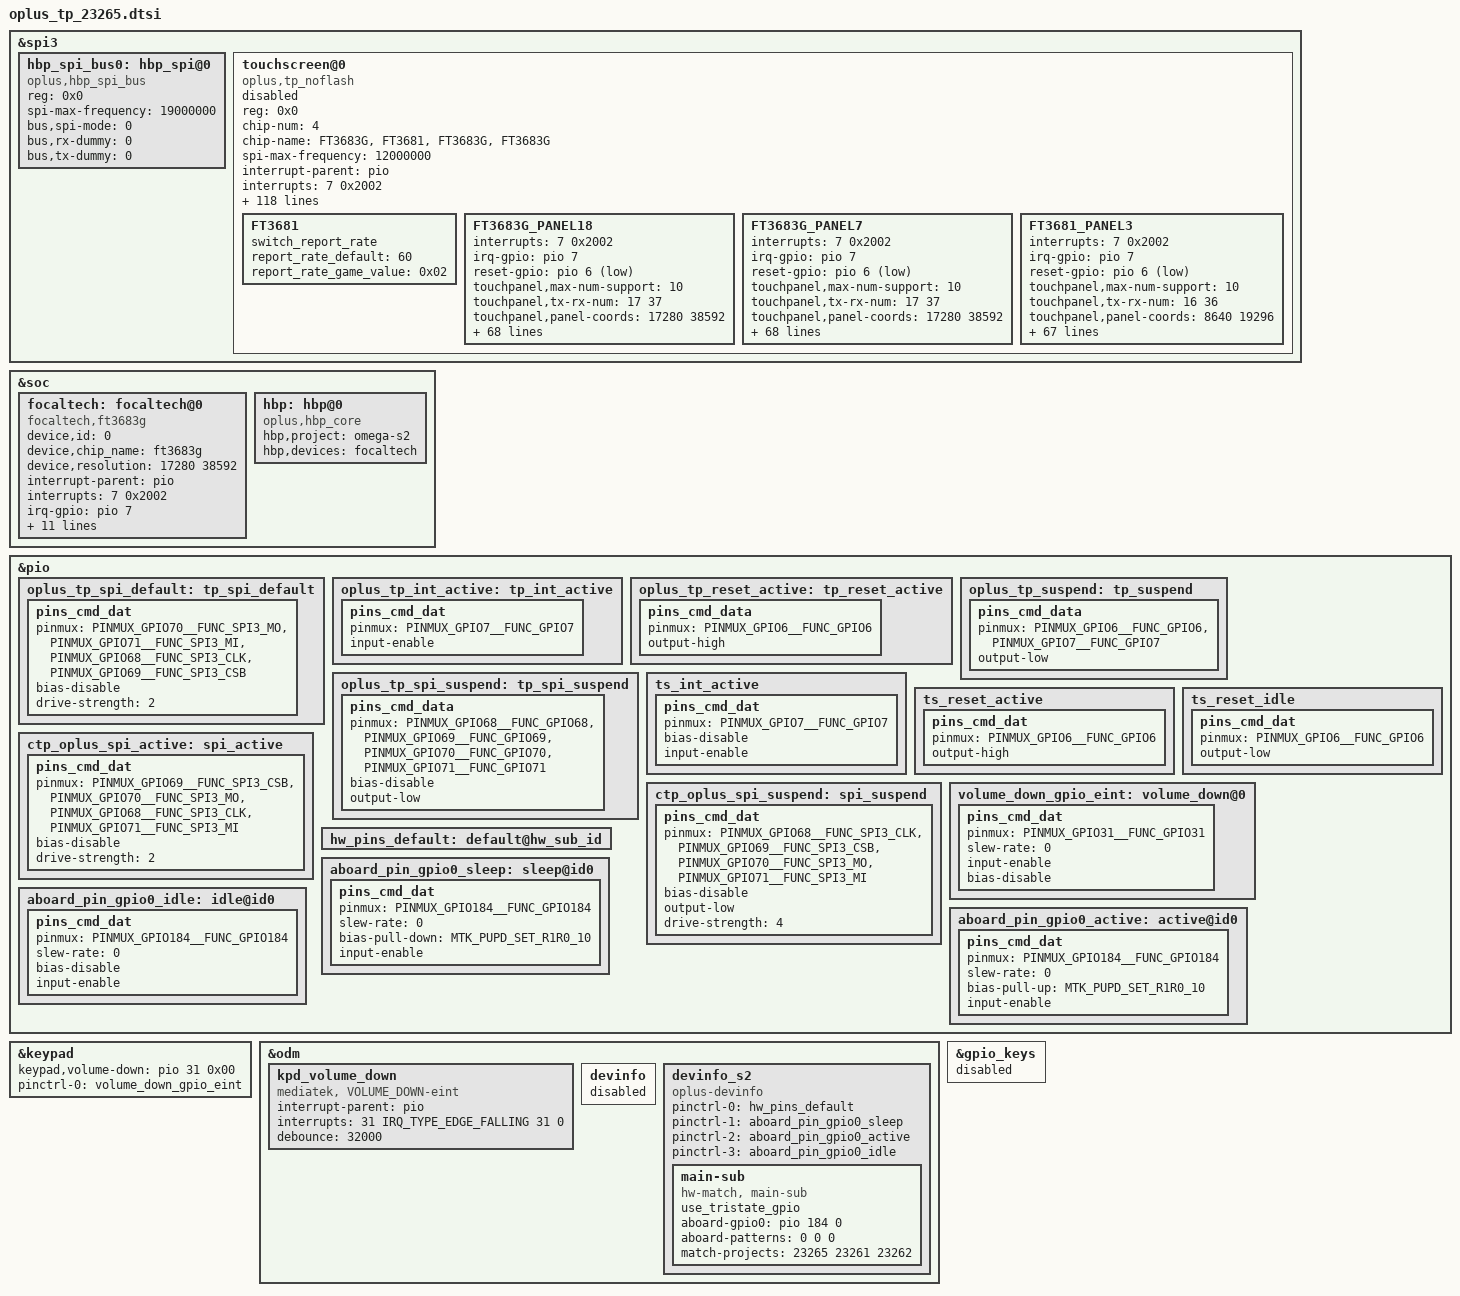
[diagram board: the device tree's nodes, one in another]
&spi3 {
	status = "okay";
	#address-cells = <1>;
	#size-cells = <0>;

	hbp_spi_bus0:hbp_spi@0 {
		compatible = "oplus,hbp_spi_bus";
		reg = <0x0>;
		status = "okay";

		spi-max-frequency = <19000000>;
		bus,spi-mode = <0>;
		bus,rx-dummy = <0>;
		bus,tx-dummy = <0>;
	};

	touchscreen@0{
		compatible = "oplus,tp_noflash";
		reg = <0x0>;
		chip-num = <4>;
		chip-name = "FT3683G", "FT3681", "FT3683G", "FT3683G";
		status = "disabled";
		spi-max-frequency = <12000000>;
		/* Interrupt && Irq-gpio */
		interrupt-parent = <&pio>;
		interrupts = <7 0x2002>;

		/* Power Config */
		vdd_2v8-supply  = <&wl28681c1_ldo6a>;
		vdd_2v8_volt = <3204000>;
		vcc_1v8-supply  = <&mt6369_vtp>;
		vcc_1v8_volt = <1800000>;


		/* Other HW Resource */

		irq-gpio = <&pio 7 0x2002>;
		reset-gpio = <&pio 6 0x1>;

		pinctrl-names = "default",  "sleep";
		pinctrl-0 = <&oplus_tp_int_active &oplus_tp_reset_active &oplus_tp_spi_default>;
		pinctrl-1 = <&oplus_tp_suspend &oplus_tp_spi_suspend>;

		touchpanel,max-num-support = <10>;
		touchpanel,tx-rx-num = <17 37>;
		touchpanel,panel-coords = <17280 38592>;
		touchpanel,display-coords = <1080 2412>;
		touchpanel,touchmajor-limit = <128 216>;
		//touchpanel,elimination-range = <20 200 200>;
		//touchpanel,int-mode = <1>; /*0: interrupt and disable, 1:interrupt and not disable*/
		touchpanel,smooth-level = <0 110 115 120 140 155>;
		touchpanel,smooth-level-charging = <0 110 115 120 140 155>;
		touchpanel,sensitive-level = <0 19 16 12 11 10>;
		touchpanel,tp-index = <0>;
		touchpanel,high-frame-rate-time = <60>;
		disable_suspend_irq_handler_support;

		vid_len = <2>;
		firmware_name = "0xAC16400", "0xAC16401", "0xAC15800", "AC15801";
		panel_type = <7 3 7 18>; /* panel-BOE*/
		platform_support_project = <23265 23262 23261>;
		platform_support_project_dir = <23265 23265 23265>;
		platform_support_project_commandline = "ac164_p_7_a0001_cmd_panel_lcm_drv", "ac164_p_3_a0001_cmd_panel_lcm_drv", "ac158_p_7_a0001_cmd_panel_lcm_drv", "ac158_p_b_a0012_cmd_panel_lcm_drv";

		prevention,curved_screen_V2;
		prevention,grip_disable_level = <6>;
		prevention,updelay_time_ms = <30>;
		prevention,makeup_cnt_weight = <4 1 2 2 2>;
		prevention,large_corner_range = <1920 4800>;
		prevention,large_corner_judge_condition = <500 300 1600 6 6>;
		prevention,trx_reject_condition = <8 7 7>;
		prevention,trx_strict_reject_condition = <7 6 6>;
		prevention,large_judge_time_ms = <500 50 30>;
		prevention,large_exit_condition = <15 12 2>;
		prevention,single_channel_width = <256 256>;
		prevention,normal_tap_condition = <10 300>;
		prevention,long_edge_condition = <230 100 180 80>;
		prevention,long_strict_edge_condition = <170 80>;
		prevention,long_fingerhold_condition = <50 6 4 4>;
		prevention,short_edge_condition = <230 100 180 80>;
		prevention,short_strict_edge_condition = <160 60>;
		prevention,large_strict_exit_condition = <5 5>;
		prevention,top_corner_config = <800 2400 720>;
		prevention,edge_swipe_config = <480 1600>;

		prevention,curved_screen_V4;
		prevention,long_eliminate_point_type = <2 17280 13280 420 38592 300 1>;
		prevention,long_fingerhold_condition2 = <1120 3200 0 0>;
		prevention,top_corner_config2 =<3 80 420 2400 0>;
		prevention,hor_long_top_corner_config =<480 3200 0 0>;
		prevention,top_middle_config =<17280 1600 1600 0>;
		prevention,corner_eliminate_point_type =<0 1920 3200 1>;
		prevention,finger_hold_differ_size = <1 0 720 300>;
		prevention,finger_hold_max_rx_exit_distance = <5 700 3400>;
		prevention,max_rx_exit_distance = <1 5 18 700 2800>;
		prevention,dynamic_finger_hold_exit_distance = <1 580 3400 780>;
		prevention,edge_sliding_matched_support = <1 250 3 0>;

		//grip v4.2 reclining mode
		prevention,reclining_mode_support = <1>;
		prevention,long_eliminate_point_type_recli = <2 17280 13280 420 38592 200 1>;
		prevention,finger_hold_differ_size_recli = <1 0 720 300>;
		prevention,finger_hold_max_rx_exit_distance_recli = <5 700 3400>;
		prevention,max_rx_exit_distance_recli = <1 5 90 700 2800>;
		prevention,dynamic_finger_hold_exit_distance_recli = <1 580 3400 780>;
		prevention,edge_sliding_matched_support_recli = <1 200 3 0>;
		prevention,long_edge_condition_recli = <120 100 150 100>;

		/* SW Support Feature Control */
		//esd_handle_support;
		//register-is-16bit;
		//wireless_charger_support;
		headset_pump_support;
		//fw_edge_limit_support;

		health_monitor_v2_support;
		black_gesture_support;
		charger_pump_support;
		lcd_tp_refresh_support;
		fw_update_app_support;
		smart_gesture_support;
		game_switch_support;
		report_flow_unlock_support;
		kernel_grip_support;
		fingerprint_underscreen_support;
		pressure_report_support;
		touchpanel,single-optimized-time = <8>;
		//report_rate_white_list_support;
		auto_test_force_pass_support;
		snr_read_support;
		//high_resolution_support;
		screenoff_fingerprint_info_support;
		irq_need_dev_resume_ok;
		sportify_aod_gesture_support;
		black_gesture_indep_support;
		thermal_detect_support;
		exception_upload_support;
		tp_data_record_support;
		palm_to_sleep_support;

		/*
		 *Virtual Key Config:
		 *1:touchpanel,button-type: <virtualkey_type  supportted_button-map>
		 *virtualkey_type:
		 *Type 1: using board_properties
		 *Type 2: using same IC (button zone&& touch zone are seprate)
		 *Type 3: using diffrent IC (button zone&& touch zone are seprate)
		 *Type 4: No need of virtual key process
		 *supportted_button-map:select|menu|home|back
		 *
		 *2:touchpanel,button-map
		 *type (X1,Y1)(X2,Y2)(X3,Y3)(Width_X,Hight_Y)--Only when button-type is 0
		 */
		touchpanel,button-type = <4>;
		touchpanel.button-TRx = <0 0>;

		FT3681 {
			switch_report_rate;
			report_rate_default = <60>;
			report_rate_game_value = <0x02>;
		};

		FT3683G_PANEL18 {
			interrupts = <7 0x2002>;
			irq-gpio = <&pio 7 0x2002>;
			reset-gpio = <&pio 6 0x1>;

			touchpanel,max-num-support = <10>;
			touchpanel,tx-rx-num = <17 37>;
			touchpanel,panel-coords = <17280 38592>;
			touchpanel,display-coords = <1080 2412>;
			touchpanel,touchmajor-limit = <128 216>;
			//touchpanel,elimination-range = <20 200 200>;
			//touchpanel,int-mode = <1>; /*0: interrupt and disable, 1:interrupt and not disable*/
			touchpanel,smooth-level = <0 110 115 120 140 155>;
			touchpanel,smooth-level-charging = <0 110 115 120 140 155>;
			touchpanel,sensitive-level = <0 19 16 12 11 10>;
			touchpanel,tp-index = <0>;
			touchpanel,high-frame-rate-time = <60>;

			prevention,curved_screen_V2;
			prevention,grip_disable_level = <6>;
			prevention,updelay_time_ms = <30>;
			prevention,makeup_cnt_weight = <4 1 2 2 2>;
			prevention,large_corner_range = <1920 4800>;
			prevention,large_corner_judge_condition = <500 300 1600 6 6>;
			prevention,trx_reject_condition = <8 7 7>;
			prevention,trx_strict_reject_condition = <7 6 6>;
			prevention,large_judge_time_ms = <500 50 30>;
			prevention,large_exit_condition = <15 12 2>;
			prevention,single_channel_width = <256 256>;
			prevention,normal_tap_condition = <10 300>;
			prevention,long_edge_condition = <230 100 180 80>;
			prevention,long_strict_edge_condition = <170 80>;
			prevention,long_fingerhold_condition = <50 6 4 4>;
			prevention,short_edge_condition = <230 100 180 80>;
			prevention,short_strict_edge_condition = <160 60>;
			prevention,large_strict_exit_condition = <5 5>;
			prevention,top_corner_config = <800 2400 720>;
			prevention,edge_swipe_config = <480 1600>;

			prevention,curved_screen_V4;
			prevention,long_eliminate_point_type = <2 17280 13280 420 38592 300 1>;
			prevention,long_fingerhold_condition2 = <1120 3200 0 0>;
			prevention,top_corner_config2 =<3 80 420 2400 0>;
			prevention,hor_long_top_corner_config =<480 3200 0 0>;
			prevention,top_middle_config =<17280 1600 1600 0>;
			prevention,corner_eliminate_point_type =<0 1920 3200 1>;
			prevention,finger_hold_differ_size = <1 0 720 300>;
			prevention,finger_hold_max_rx_exit_distance = <5 700 3400>;
			prevention,max_rx_exit_distance = <1 5 18 700 2800>;
			prevention,dynamic_finger_hold_exit_distance = <1 580 3400 780>;
			prevention,edge_sliding_matched_support = <1 250 3 0>;

			//grip v4.2 reclining mode
			prevention,reclining_mode_support = <1>;
			prevention,long_eliminate_point_type_recli = <2 17280 13280 420 38592 200 1>;
			prevention,finger_hold_differ_size_recli = <1 0 720 300>;
			prevention,finger_hold_max_rx_exit_distance_recli = <5 700 3400>;
			prevention,max_rx_exit_distance_recli = <1 5 90 700 2800>;
			prevention,dynamic_finger_hold_exit_distance_recli = <1 580 3400 780>;
			prevention,edge_sliding_matched_support_recli = <1 200 3 0>;
			prevention,long_edge_condition_recli = <120 100 150 100>;

			tp_data_record_support;
		};


		FT3683G_PANEL7 {
			interrupts = <7 0x2002>;
			irq-gpio = <&pio 7 0x2002>;
			reset-gpio = <&pio 6 0x1>;

			touchpanel,max-num-support = <10>;
			touchpanel,tx-rx-num = <17 37>;
			touchpanel,panel-coords = <17280 38592>;
			touchpanel,display-coords = <1080 2412>;
			touchpanel,touchmajor-limit = <128 216>;
			//touchpanel,elimination-range = <20 200 200>;
			//touchpanel,int-mode = <1>; /*0: interrupt and disable, 1:interrupt and not disable*/
			touchpanel,smooth-level = <0 110 115 120 140 155>;
			touchpanel,smooth-level-charging = <0 110 115 120 140 155>;
			touchpanel,sensitive-level = <0 19 16 12 11 10>;
			touchpanel,tp-index = <0>;
			touchpanel,high-frame-rate-time = <60>;

			prevention,curved_screen_V2;
			prevention,grip_disable_level = <6>;
			prevention,updelay_time_ms = <30>;
			prevention,makeup_cnt_weight = <4 1 2 2 2>;
			prevention,large_corner_range = <1920 4800>;
			prevention,large_corner_judge_condition = <500 300 1600 6 6>;
			prevention,trx_reject_condition = <8 7 7>;
			prevention,trx_strict_reject_condition = <7 6 6>;
			prevention,large_judge_time_ms = <500 50 30>;
			prevention,large_exit_condition = <15 12 2>;
			prevention,single_channel_width = <256 256>;
			prevention,normal_tap_condition = <10 300>;
			prevention,long_edge_condition = <230 100 180 80>;
			prevention,long_strict_edge_condition = <170 80>;
			prevention,long_fingerhold_condition = <50 6 4 4>;
			prevention,short_edge_condition = <230 100 180 80>;
			prevention,short_strict_edge_condition = <160 60>;
			prevention,large_strict_exit_condition = <5 5>;
			prevention,top_corner_config = <800 2400 720>;
			prevention,edge_swipe_config = <480 1600>;

			prevention,curved_screen_V4;
			prevention,long_eliminate_point_type = <2 17280 13280 420 38592 300 1>;
			prevention,long_fingerhold_condition2 = <1120 3200 0 0>;
			prevention,top_corner_config2 =<3 80 420 2400 0>;
			prevention,hor_long_top_corner_config =<480 3200 0 0>;
			prevention,top_middle_config =<17280 1600 1600 0>;
			prevention,corner_eliminate_point_type =<0 1920 3200 1>;
			prevention,finger_hold_differ_size = <1 0 720 300>;
			prevention,finger_hold_max_rx_exit_distance = <5 700 3400>;
			prevention,max_rx_exit_distance = <1 5 18 700 2800>;
			prevention,dynamic_finger_hold_exit_distance = <1 580 3400 780>;
			prevention,edge_sliding_matched_support = <1 250 3 0>;

			//grip v4.2 reclining mode
			prevention,reclining_mode_support = <1>;
			prevention,long_eliminate_point_type_recli = <2 17280 13280 420 38592 200 1>;
			prevention,finger_hold_differ_size_recli = <1 0 720 300>;
			prevention,finger_hold_max_rx_exit_distance_recli = <5 700 3400>;
			prevention,max_rx_exit_distance_recli = <1 5 90 700 2800>;
			prevention,dynamic_finger_hold_exit_distance_recli = <1 580 3400 780>;
			prevention,edge_sliding_matched_support_recli = <1 200 3 0>;
			prevention,long_edge_condition_recli = <120 100 150 100>;

			tp_data_record_support;
		};

		FT3681_PANEL3 {
			interrupts = <7 0x2002>;
			irq-gpio = <&pio 7 0x2002>;
			reset-gpio = <&pio 6 0x1>;

			touchpanel,max-num-support = <10>;
			touchpanel,tx-rx-num = <16 36>;
			touchpanel,panel-coords = <8640 19296>;
			touchpanel,display-coords = <1080 2412>;
			touchpanel,touchmajor-limit = <128 216>;
			//touchpanel,elimination-range = <20 200 200>;
			//touchpanel,int-mode = <1>; /*0: interrupt and disable, 1:interrupt and not disable*/
			touchpanel,smooth-level = <0 110 115 120 140 155>;
			touchpanel,smooth-level-charging = <0 110 115 120 140 155>;
			touchpanel,sensitive-level = <0 19 16 12 11 10>;
			touchpanel,tp-index = <0>;
			touchpanel,high-frame-rate-time = <60>;

			prevention,curved_screen_V2;
			prevention,grip_disable_level = <6>;
			prevention,updelay_time_ms = <30>;
			prevention,makeup_cnt_weight = <4 1 2 2 2>;
			prevention,large_corner_range = <960 2400>;
			prevention,large_corner_judge_condition = <500 300 800 6 6>;
			prevention,trx_reject_condition = <8 7 7>;
			prevention,trx_strict_reject_condition = <7 6 6>;
			prevention,large_judge_time_ms = <500 50 30>;
			prevention,large_exit_condition = <15 12 2>;
			prevention,single_channel_width = <256 256>;
			prevention,normal_tap_condition = <10 300>;
			prevention,long_edge_condition = <230 100 180 80>;
			prevention,long_strict_edge_condition = <170 80>;
			prevention,long_fingerhold_condition = <50 6 4 4>;
			prevention,short_edge_condition = <230 100 180 80>;
			prevention,short_strict_edge_condition = <160 60>;
			prevention,large_strict_exit_condition = <5 5>;
			prevention,top_corner_config = <400 1200 380>;
			prevention,edge_swipe_config = <240 800>;

			prevention,curved_screen_V4;
			prevention,long_eliminate_point_type = <2 8640 6640 210 19296 300 1>;
			prevention,long_fingerhold_condition2 = <560 1600 0 0>;
			prevention,top_corner_config2 =<3 80 420 1200 0>;
			prevention,hor_long_top_corner_config =<240 1600 0 0>;
			prevention,top_middle_config =<8640 800 800 0>;
			prevention,corner_eliminate_point_type =<0 960 1600 1>;
			prevention,finger_hold_differ_size = <1 0 360 300>;
			prevention,finger_hold_max_rx_exit_distance = <5 350 1700>;
			prevention,max_rx_exit_distance = <1 5 90 350 1400>;
			prevention,dynamic_finger_hold_exit_distance = <1 290 1700 390>;
			prevention,edge_sliding_matched_support = <1 250 3 0>;

			//grip v4.2 reclining mode
			prevention,reclining_mode_support = <1>;
			prevention,long_eliminate_point_type_recli = <2 8640 6640 210 19296 200 1>;
			prevention,finger_hold_differ_size_recli = <1 0 360 300>;
			prevention,finger_hold_max_rx_exit_distance_recli = <5 350 1700>;
			prevention,max_rx_exit_distance_recli = <1 5 90 350 1400>;
			prevention,dynamic_finger_hold_exit_distance_recli = <1 290 1700 390>;
			prevention,edge_sliding_matched_support_recli = <1 200 3 0>;
			prevention,long_edge_condition_recli = <120 100 150 100>;

			tp_data_record_support;
		};
	};
};

&soc {
	focaltech:focaltech@0 {
		compatible = "focaltech,ft3683g";
		status = "okay";

		device,id = <0>;
		device,chip_name = "ft3683g";
		device,resolution = <17280 38592>;

		/*interrupt config*/
		interrupt-parent = <&pio>;
		interrupts = <7 0x2002>;
		irq-gpio = <&pio 7 0x2002>;

		pinctrl-names = "default",
			"ts_reset_active",
			"ts_reset_idle",
			"ts_resume",
			"ts_suspend";
		pinctrl-0 = <&ts_int_active &ts_reset_active>;
		pinctrl-1 = <&ts_reset_active>;
		pinctrl-2 = <&ts_reset_idle>;
		pinctrl-3 = <&ctp_oplus_spi_active>;
		pinctrl-4 = <&ctp_oplus_spi_suspend>;

		/*cs active state, not used now*/
		spi,cs_active = <0>;

		/*power config*/
		power,avdd-supply = <&wl28681c1_ldo6a>;
		power,avdd_volt = <3204000 3204000>;
		power,vddi-supply = <&mt6369_vtp>;
		power,vddi_volt = <1800000 1800000>;

		/*bus config*/
		device,attached_bus = <&hbp_spi_bus0>;
	};

	hbp:hbp@0 {
		compatible = "oplus,hbp_core";
		hbp,project = "omega-s2";
		hbp,devices = <&focaltech>;
	};
};

&pio {
	oplus_tp_spi_default: tp_spi_default {
		pins_cmd_dat {
			pinmux = <PINMUX_GPIO70__FUNC_SPI3_MO>,
				<PINMUX_GPIO71__FUNC_SPI3_MI>,
				<PINMUX_GPIO68__FUNC_SPI3_CLK>,
				<PINMUX_GPIO69__FUNC_SPI3_CSB>;
			bias-disable;
			drive-strength = <2>;
		};
	};

	oplus_tp_int_active: tp_int_active {
		pins_cmd_dat {
			pinmux = <PINMUX_GPIO7__FUNC_GPIO7>;
			input-enable;
		};
	};
	oplus_tp_reset_active: tp_reset_active {
		pins_cmd_data {
			pinmux = <PINMUX_GPIO6__FUNC_GPIO6>;
			output-high;
		};
	};
	oplus_tp_suspend: tp_suspend {
		pins_cmd_data {
			pinmux = <PINMUX_GPIO6__FUNC_GPIO6>,
					<PINMUX_GPIO7__FUNC_GPIO7>;
			output-low;
		};
	};
	oplus_tp_spi_suspend: tp_spi_suspend {
		pins_cmd_data {
			pinmux = <PINMUX_GPIO68__FUNC_GPIO68>,
					<PINMUX_GPIO69__FUNC_GPIO69>,
					<PINMUX_GPIO70__FUNC_GPIO70>,
					<PINMUX_GPIO71__FUNC_GPIO71>;
			bias-disable;
			output-low;
		};
	};

	/*add for omega TP*/
	ts_int_active: ts_int_active {
		pins_cmd_dat {
			pinmux = <PINMUX_GPIO7__FUNC_GPIO7>;
			bias-disable;
			input-enable;
		};
	};
	ts_reset_active: ts_reset_active {
		pins_cmd_dat {
			pinmux = <PINMUX_GPIO6__FUNC_GPIO6>;
			output-high;
		};
	};
	ts_reset_idle: ts_reset_idle {
		pins_cmd_dat {
			pinmux = <PINMUX_GPIO6__FUNC_GPIO6>;
			output-low;
		};
	};
	ctp_oplus_spi_active: spi_active {
		pins_cmd_dat {
			pinmux = <PINMUX_GPIO69__FUNC_SPI3_CSB>,
				<PINMUX_GPIO70__FUNC_SPI3_MO>,
				<PINMUX_GPIO68__FUNC_SPI3_CLK>,
				<PINMUX_GPIO71__FUNC_SPI3_MI>;
			bias-disable;
			drive-strength = <2>;
		};
	};
	ctp_oplus_spi_suspend: spi_suspend {
		pins_cmd_dat {
			pinmux = <PINMUX_GPIO68__FUNC_SPI3_CLK>,
					<PINMUX_GPIO69__FUNC_SPI3_CSB>,
					<PINMUX_GPIO70__FUNC_SPI3_MO>,
					<PINMUX_GPIO71__FUNC_SPI3_MI>;
			bias-disable;
			output-low;
			drive-strength = <4>;
		};
	};
};

&keypad {
        keypad,volume-down = <&pio 31 0x00>;
        pinctrl-names = "volume_down_as_int";
        pinctrl-0 = <&volume_down_gpio_eint>;
        status = "okay";
};

&pio {
        volume_down_gpio_eint:volume_down@0{
                pins_cmd_dat {
                        pinmux = <PINMUX_GPIO31__FUNC_GPIO31>;
                        slew-rate = <0>;  /*direction 0:in, 1:out*/
                        input-enable;
                        bias-disable;
                };
        };
};

&odm {
        kpd_volume_down:kpd_volume_down {
                compatible = "mediatek, VOLUME_DOWN-eint";
                interrupt-parent = <&pio>;
                interrupts = <31 IRQ_TYPE_EDGE_FALLING 31 0>;
                debounce = <32000>;
                status = "okay";
        };
};

&odm {
	devinfo {
		status = "disabled";
	};

	devinfo_s2 {
		compatible = "oplus-devinfo";

		pinctrl-names = "default", "aboard_gpio0_sleep", "aboard_gpio0_active", "aboard_gpio0_idle";
		pinctrl-0 = <&hw_pins_default>;
		pinctrl-1 = <&aboard_pin_gpio0_sleep>;
		pinctrl-2 = <&aboard_pin_gpio0_active>;
		pinctrl-3 = <&aboard_pin_gpio0_idle>;

		main-sub {
			compatible = "hw-match, main-sub";
			use_tristate_gpio;
			aboard-gpio0 = <&pio 184 0>;
			aboard-patterns = <0 0 0>;	/*0[high-resistance] 1[pull-down] 2[pull-up]*/
			/*main board*/
			match-projects = <23265 23261 23262>;
		};
	};
};

&pio{
	hw_pins_default:default@hw_sub_id {
	};

	aboard_pin_gpio0_sleep:sleep@id0 {
		pins_cmd_dat {
			pinmux = <PINMUX_GPIO184__FUNC_GPIO184>;
			slew-rate = <0>;
			bias-pull-down = <MTK_PUPD_SET_R1R0_10>;
			input-enable;
		};
	};

	aboard_pin_gpio0_active:active@id0 {
		pins_cmd_dat {
			pinmux = <PINMUX_GPIO184__FUNC_GPIO184>;
			slew-rate = <0>;
			bias-pull-up = <MTK_PUPD_SET_R1R0_10>;
			input-enable;
		};
	};

	aboard_pin_gpio0_idle:idle@id0 {
		pins_cmd_dat {
			pinmux = <PINMUX_GPIO184__FUNC_GPIO184>;
			slew-rate = <0>;
			bias-disable;
			input-enable;
		};
	};
};

&gpio_keys {
	status = "disabled";
};
